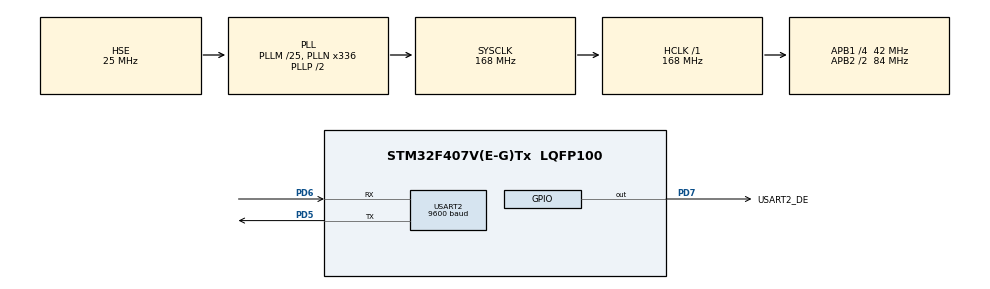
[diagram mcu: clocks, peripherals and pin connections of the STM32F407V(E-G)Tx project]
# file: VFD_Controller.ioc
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Mcu.Family=STM32F4
Mcu.Name=STM32F407V(E-G)Tx
Mcu.Package=LQFP100
NVIC.PriorityGroup=NVIC_PRIORITYGROUP_4
PD5.Mode=Asynchronous
PD5.Signal=USART2_TX
PD6.Mode=Asynchronous
PD6.Signal=USART2_RX
PD7.GPIO_Label=USART2_DE
PD7.Signal=GPIO_Output
PH0-OSC_IN.Mode=HSE-External-Oscillator
PH0-OSC_IN.Signal=RCC_OSC_IN
PH1-OSC_OUT.Mode=HSE-External-Oscillator
PH1-OSC_OUT.Signal=RCC_OSC_OUT
ProjectManager.HeapSize=0x200
ProjectManager.StackSize=0x400
ProjectManager.TargetToolchain=STM32CubeIDE
RCC.48MHZClocksFreq_Value=48000000
RCC.AHBFreq_Value=168000000
RCC.APB1CLKDivider=RCC_HCLK_DIV4
RCC.APB1Freq_Value=42000000
RCC.APB1TimFreq_Value=84000000
RCC.APB2CLKDivider=RCC_HCLK_DIV2
RCC.APB2Freq_Value=84000000
RCC.APB2TimFreq_Value=168000000
RCC.CortexFreq_Value=168000000
RCC.HCLKFreq_Value=168000000
RCC.HSE_VALUE=25000000
RCC.HSI_VALUE=16000000
RCC.LSE_VALUE=32768
RCC.PLLM=25
RCC.PLLN=336
RCC.PLLQ=7
RCC.PLLSourceVirtual=RCC_PLLSOURCE_HSE
RCC.SYSCLKFreq_VALUE=168000000
RCC.SYSCLKSource=RCC_SYSCLKSOURCE_PLLCLK
RCC.VCOOutputFreq_Value=336000000
USART2.BaudRate=9600
USART2.StopBits=STOPBITS_2
USART2.VirtualMode=VM_ASYNC
board=custom

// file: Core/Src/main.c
/* USER CODE BEGIN Header */
/**
 ******************************************************************************
 * @file           : main.c
 * @brief          : Main program body
 ******************************************************************************
 * @attention
 *
 * Copyright (c) 2025 STMicroelectronics.
 * All rights reserved.
 *
 * This software is licensed under terms that can be found in the LICENSE file
 * in the root directory of this software component.
 * If no LICENSE file comes with this software, it is provided AS-IS.
 *
 ******************************************************************************
 */
/* USER CODE END Header */
#include "main.h"

#include "gpio.h"
#include "usart.h"

/* USER CODE BEGIN Includes */
#include "mmodbus.h"
#include "vfd_controller.h"
/* USER CODE END Includes */

void SystemClock_Config(void);
/* USER CODE BEGIN PFP */
void HAL_UART_RxCpltCallback(UART_HandleTypeDef *huart);
// Modbus wrapper prototypes (to fix undeclared errors)
vfd_issue my_mb_write_single_reg(uint16_t slave, uint16_t addr, uint16_t val);
vfd_issue my_mb_read_single_reg(uint16_t slave, uint16_t addr, uint16_t *val);
vfd_issue my_mb_read_multi_reg(uint16_t slave, uint16_t addr, uint16_t count, uint16_t *buf);
/* USER CODE END PFP */

int main(void) {

	/* MCU Configuration--------------------------------------------------------*/

	/* Reset of all peripherals, Initializes the Flash interface and the Systick. */
	HAL_Init();

	/* Configure the system clock */
	SystemClock_Config();

	/* Initialize all configured peripherals */
	MX_GPIO_Init();
	MX_USART2_UART_Init();
	/* USER CODE BEGIN 2 */
	mmodbus_init(2500);

	/* USER CODE END 2 */

	/* Infinite loop */
	/* USER CODE BEGIN WHILE */
	mmodbus_writeHoldingRegister16i(16, 40960, 1);

	/*uint32_t last_time = HAL_GetTick();
	int32_t freq=0;
	int32_t step=1000;*/
	vfd_context_t ctx;
	ctx.slave_address = 16;
	ctx.mb_write_single_reg = my_mb_write_single_reg;
	ctx.mb_write_multi_reg = NULL;	// If not used
	ctx.mb_read_single_reg = my_mb_read_single_reg;
	ctx.mb_read_multi_reg = my_mb_read_multi_reg;

	vfd_init(&ctx);  // Use default Delixi config

	// Example control
	vfd_set_running_freq(&ctx, 50.0);  // 50 %
	uint32_t last_time = HAL_GetTick();
	float freq = 0;  // Start at 0 (0.00%)
	int32_t step = 1;  // 10.00% step (1000 * 0.01 = 10%)
	while (1) {
		/* USER CODE END WHILE */
		vfd_update(&ctx);  // reads all registers and updates the internal data.
		uint32_t now = HAL_GetTick();

		if (now - last_time > 500) {
			vfd_set_running_freq(&ctx, freq);
			freq += step;

			if (freq >= 99) step = -1;

			if (freq < 5) step = 1;

			last_time = now;
		}

	}
}

void SystemClock_Config(void) {
	RCC_OscInitTypeDef RCC_OscInitStruct = {0};
	RCC_ClkInitTypeDef RCC_ClkInitStruct = {0};

	/** Configure the main internal regulator output voltage
	 */
	__HAL_RCC_PWR_CLK_ENABLE();
	__HAL_PWR_VOLTAGESCALING_CONFIG(PWR_REGULATOR_VOLTAGE_SCALE1);

	/** Initializes the RCC Oscillators according to the specified parameters
	 * in the RCC_OscInitTypeDef structure.
	 */
	RCC_OscInitStruct.OscillatorType = RCC_OSCILLATORTYPE_HSE;
	RCC_OscInitStruct.HSEState = RCC_HSE_ON;
	RCC_OscInitStruct.PLL.PLLState = RCC_PLL_ON;
	RCC_OscInitStruct.PLL.PLLSource = RCC_PLLSOURCE_HSE;
	RCC_OscInitStruct.PLL.PLLM = 25;
	RCC_OscInitStruct.PLL.PLLN = 336;
	RCC_OscInitStruct.PLL.PLLP = RCC_PLLP_DIV2;
	RCC_OscInitStruct.PLL.PLLQ = 7;
	if (HAL_RCC_OscConfig(&RCC_OscInitStruct) != HAL_OK) {
		Error_Handler();
	}

	/** Initializes the CPU, AHB and APB buses clocks
	 */
	RCC_ClkInitStruct.ClockType =
		RCC_CLOCKTYPE_HCLK | RCC_CLOCKTYPE_SYSCLK | RCC_CLOCKTYPE_PCLK1 | RCC_CLOCKTYPE_PCLK2;
	RCC_ClkInitStruct.SYSCLKSource = RCC_SYSCLKSOURCE_PLLCLK;
	RCC_ClkInitStruct.AHBCLKDivider = RCC_SYSCLK_DIV1;
	RCC_ClkInitStruct.APB1CLKDivider = RCC_HCLK_DIV4;
	RCC_ClkInitStruct.APB2CLKDivider = RCC_HCLK_DIV2;

	if (HAL_RCC_ClockConfig(&RCC_ClkInitStruct, FLASH_LATENCY_5) != HAL_OK) {
		Error_Handler();
	}
}

/* USER CODE BEGIN 4 */
void HAL_UART_RxCpltCallback(UART_HandleTypeDef *huart) { mmodbus_callback(); }

// Modbus wrapper functions (implement based on mmodbus API; assume it returns 0 on success)
vfd_issue my_mb_write_single_reg(uint16_t slave, uint16_t addr, uint16_t val) {
    int result = mmodbus_writeHoldingRegister16i(slave, addr, val);
    return (result == 0) ? VFD_SUCCESS : VFD_ERROR_MODBUS_FAIL;  // Adjust if mmodbus returns error codes
}

vfd_issue my_mb_read_single_reg(uint16_t slave, uint16_t addr, uint16_t *val) {
    int result = mmodbus_readHoldingRegister16i(slave, addr, val);  // Assume this exists in mmodbus.h
    return (result == 0) ? VFD_SUCCESS : VFD_ERROR_MODBUS_FAIL;
}

vfd_issue my_mb_read_multi_reg(uint16_t slave, uint16_t addr, uint16_t count, uint16_t *buf) {
    int result = mmodbus_readHoldingRegisters16i(slave, addr, count, buf);  // Assume multi-read API
    return (result == 0) ? VFD_SUCCESS : VFD_ERROR_MODBUS_FAIL;
}

/* USER CODE END 4 */

void Error_Handler(void) {
	__disable_irq();
	while (1) {
	}
}
